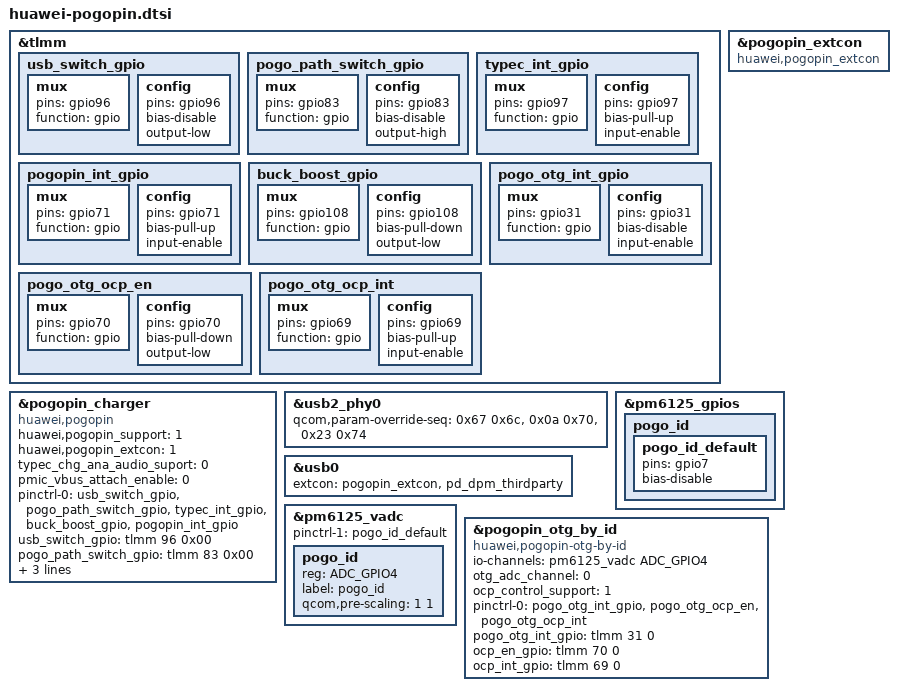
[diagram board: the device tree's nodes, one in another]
&tlmm {
	usb_switch_gpio:usb_switch_gpio {
		mux{
			pins = "gpio96";
			function = "gpio";
		};

		config {
			pins = "gpio96";
			bias-disable;
			output-low;
		};
	};

	pogo_path_switch_gpio:pogo_path_switch_gpio {
		mux{
			pins = "gpio83";
			function = "gpio";
		};

		config {
			pins = "gpio83";
			bias-disable;
			output-high;
		};
	};

	typec_int_gpio:typec_int_gpio {
		mux{
			pins = "gpio97";
			function = "gpio";
		};

		config {
			pins = "gpio97";
			bias-pull-up;
			input-enable;
		};
	};

	pogopin_int_gpio:pogopin_int_gpio {
		mux{
			pins = "gpio71";
			function = "gpio";
		};

		config {
			pins = "gpio71";
			bias-pull-up;
			input-enable;
		};
	};

	buck_boost_gpio:buck_boost_gpio {
		mux{
			pins = "gpio108";
			function = "gpio";
	};

		config {
			pins = "gpio108";
			bias-pull-down;
			output-low;
		};
	};

	pogo_otg_int_gpio:pogo_otg_int_gpio {
		mux{
			pins = "gpio31";
			function = "gpio";
		};

		config {
			pins = "gpio31";
			bias-disable;
			input-enable;
		};
	};

	pogo_otg_ocp_en:pogo_otg_ocp_en {
		mux{
			pins = "gpio70";
			function = "gpio";
		};

		config {
			pins = "gpio70";
			bias-pull-down;
			output-low;
		};
	};

	pogo_otg_ocp_int:pogo_otg_ocp_int {
		mux{
			pins = "gpio69";
			function = "gpio";
		};

		config {
			pins = "gpio69";
			bias-pull-up;
			input-enable;
		};
	};
};

&pogopin_charger {
	compatible = "huawei,pogopin";
	huawei,pogopin_support = <1>;
	huawei,pogopin_extcon =  <1>;
	typec_chg_ana_audio_suport = <0>;
	pmic_vbus_attach_enable = <0>;
	pinctrl-names = "default";
	pinctrl-0 = <&usb_switch_gpio &pogo_path_switch_gpio &typec_int_gpio &buck_boost_gpio &pogopin_int_gpio>;
	usb_switch_gpio = <&tlmm 96 0x00>;
	pogo_path_switch_gpio = <&tlmm 83 0x00>;
	typec_int_gpio = <&tlmm 97 0x00>;
	pogopin_int_gpio = <&tlmm 71 0x00>;
	buck_boost_gpio = <&tlmm 108 0>;
	status = "ok";
};

&usb2_phy0{
	qcom,param-override-seq = <0x67 0x6c>, //override_x0
				  <0x0a 0x70>, //override_x1
				  <0x23 0x74>; //override_x2
};

&pogopin_extcon {
	compatible = "huawei,pogopin_extcon";
	status = "ok";
};

&usb0 {
	extcon = <&pogopin_extcon>, <&pd_dpm_thirdparty>;
};

&pm6125_gpios {
	pogo_id {
		pogo_id_default: pogo_id_default {
			pins = "gpio7";
			bias-disable;
		};
	};
};

&pm6125_vadc {
	pinctrl-1 = <&pogo_id_default>;

	pogo_id {
		reg = <ADC_GPIO4>;
		label = "pogo_id";
		qcom,pre-scaling = <1 1>;
	};
};

&pogopin_otg_by_id {
	compatible = "huawei,pogopin-otg-by-id";
	io-channels = <&pm6125_vadc ADC_GPIO4>;
	io-channel-names = "pogo-id";
	otg_adc_channel = <0>;
	pinctrl-names = "default";
	ocp_control_support = <1>;
	pinctrl-0 = <&pogo_otg_int_gpio &pogo_otg_ocp_en &pogo_otg_ocp_int>;
	pogo_otg_int_gpio = <&tlmm 31 0>;
	ocp_en_gpio = <&tlmm 70 0>;
	ocp_int_gpio = <&tlmm 69 0>;
	status = "ok";
};
